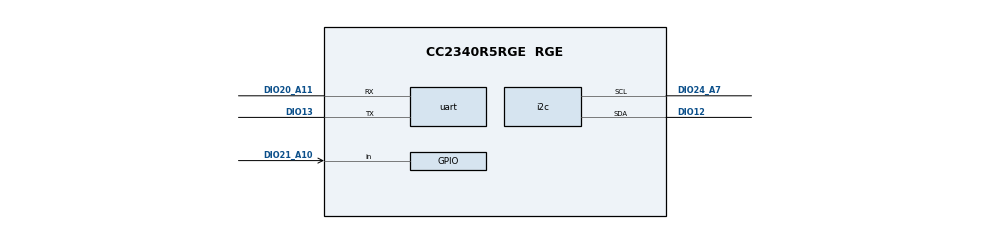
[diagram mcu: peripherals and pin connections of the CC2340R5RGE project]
// @cliArgs --device "CC2340R5RGE" --package "RGE" --rtos "freertos"

/*
 *  ble_sensor.syscfg - BSN-C23-A BLE temperature/humidity broadcaster
 *
 *  Derived from the TI LPF3 SDK basic_ble example (BSD-3-Clause).
 *  Pin map: see ../common/bsn_board.h
 */

/* ======== BLE ======== */
const ble = scripting.addModule("/ti/ble/ble");
ble.deviceRole = "BROADCASTER_CFG";
ble.deviceName = "BSN-C23";
// Use the factory-programmed public address so it matches the hwtest printout
ble.addressMode = "ADDRMODE_PUBLIC";
ble.numOfAdvSets = 1;
// Legacy non-connectable, non-scannable advertising. The app supplies the
// advertising payload (BTHome v2); only the parameters below come from here.
ble.advSet1.advParam1.advType = "legacy";
ble.advSet1.advParam1.legacyEvnPropOptions = "NC_NS";
ble.advSet1.advParam1.eventProps = ["GAP_ADV_PROP_LEGACY"];
// 1 s interval for bring-up. Raise this for battery-life measurements.
ble.advSet1.advParam1.primIntMin = 1000;
ble.advSet1.advParam1.primIntMax = 1000;

/* ======== Board ======== */
// Without a --board, the generated Board_init() still bit-bangs a LaunchPad SPI-flash
// shutdown sequence on DIO11/13/21/24, which are UART TX, HDC INT and I2C SCL here.
const Board = scripting.addModule("/ti/drivers/Board");
Board.generateInitializationFunctions = false;

/* ======== RCL ======== */
scripting.addModule("/ti/drivers/RCL");

/* ======== Power ======== */
scripting.addModule("/ti/drivers/Power");

/* ======== RNG ======== */
const RNG = scripting.addModule("/ti/drivers/RNG");
RNG.rngReturnBehavior = "RNG_RETURN_BEHAVIOR_BLOCKING";

/* ======== RF design ======== */
const rfDesign = scripting.addModule("ti/devices/radioconfig/rfdesign");
const rfDesignSettings = system.getScript("/ti/common/lprf_rf_design_settings.js").rfDesignSettings;
for (const setting in rfDesignSettings)
{
    rfDesign[setting] = rfDesignSettings[setting];
}

/* ======== Device configuration (CCFG) ======== */
const CCFG = scripting.addModule("/ti/devices/CCFG");
const ccfgSettings = system.getScript("/ti/common/lprf_ccfg_settings.js").ccfgSettings;
for (const setting in ccfgSettings)
{
    CCFG[setting] = ccfgSettings[setting];
}
// X2 (32.768 kHz crystal) is not fitted on rev A, so use the internal RC oscillator.
// The BLE module follows this and widens its sleep-clock accuracy accordingly.
CCFG.srcClkLF = "LF RCOSC";
// HFXT load-capacitance trim (internal cap array, 6 bits, 0..63). Higher values
// add load capacitance and lower the frequency. Measured at 2440 MHz: factory
// default 35 = +30.3 ppm, 39 = +16.8 ppm, 44 = +2.2 ppm
// (hardware/C23/testing/RF/RF_CARRIER.md). Keep Q1 and Q2 within one step of each
// other, and keep the same values in ble_sensor.syscfg and cwtest.syscfg.
CCFG.overrideHfxtCapArray = true;
CCFG.hfxtCapArrayQ1 = 44;
CCFG.hfxtCapArrayQ2 = 44;
// The ROM serial bootloader is disabled once this image is flashed (SDK default);
// recover over SWD with "make erase". Never enable its pin trigger: the default
// trigger pin DIO21 is the HDC2010 INT line.

/* ======== FreeRTOS ======== */
const FreeRTOS = scripting.addModule("/freertos/FreeRTOS");
scripting.addModule("/ti/posix/freertos/Settings");
const bleCommon = system.getScript("/ti/ble/.meta/ble_common.js");
// basic_ble uses 0x4D50; +0xAB0 for the sensor thread (1.5 KB) and the larger BLE task stack
FreeRTOS.heapSize = 0x00005800;
FreeRTOS.maxPriorities = 10;
bleCommon.configureTimerTaskPriority(FreeRTOS);
FreeRTOS.timerStackSize = 0x00000190;
FreeRTOS.idleStackSize = 0x00000130;

/* ======== NVS (BLE stack non-volatile storage) ======== */
const NVS = scripting.addModule("/ti/drivers/NVS");
const nvs = NVS.addInstance();
nvs.$name = "CONFIG_NVSINTERNAL";
nvs.internalFlash.regionBase = system.getScript("/ti/ble/ble_common.js").getBondNVBaseAddress();
nvs.internalFlash.regionSize = 0x3000;

/* ======== UART (log output on TP2) ======== */
const UART2 = scripting.addModule("/ti/drivers/UART2", {}, false);
const uart = UART2.addInstance();
uart.$name = "CONFIG_UART_LOG";
uart.baudRates = [115200];
uart.uart.txPin.$assign = "DIO13";
uart.uart.rxPin.$assign = "DIO20_A11";
uart.txPinInstance.initialOutputState = "High";
ble.disableDisplayModule = true;

/* ======== I2C (HDC2010 / SHTC3) ======== */
const I2C = scripting.addModule("/ti/drivers/I2C", {}, false);
const i2c = I2C.addInstance();
i2c.$name = "CONFIG_I2C_SENSOR";
i2c.i2c.sdaPin.$assign = "DIO12";
i2c.i2c.sclPin.$assign = "DIO24_A7";

/* ======== GPIO ======== */
const GPIO = scripting.addModule("/ti/drivers/GPIO");
// HDC2010 DRDY/INT. The pin is high-Z until the sensor is configured, so a pull-down
// keeps it from floating.
const hdcInt = GPIO.addInstance();
hdcInt.$name = "CONFIG_GPIO_HDC_INT";
hdcInt.mode = "Input";
hdcInt.pull = "Pull Down";
hdcInt.gpioPin.$assign = "DIO21_A10";

/* ======== Battery monitor ======== */
scripting.addModule("/ti/drivers/BatteryMonitor");
